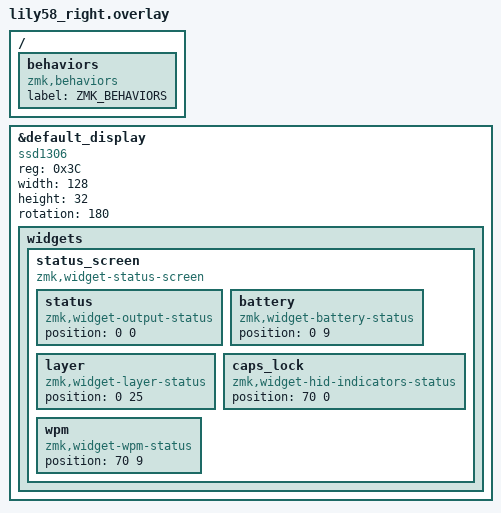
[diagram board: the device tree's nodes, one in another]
#include "../lily58.dtsi"

&default_display {
    compatible = "ssd1306";
    reg = <0x3C>;                    // I2C address
    width = <128>;
    height = <32>;
    rotation = <180>;
    status = "okay";

    widgets {
        status_screen {
            compatible = "zmk,widget-status-screen";
            status {
                compatible = "zmk,widget-output-status";
                position = <0 0>;
            };
            battery {
                compatible = "zmk,widget-battery-status";
                position = <0 9>;
            };
            layer {
                compatible = "zmk,widget-layer-status";
                position = <0 25>;
            };
             caps_lock {
                compatible = "zmk,widget-hid-indicators-status";
                position = <70 0>; // Example position (adjust as needed)
            };
            wpm {
                compatible = "zmk,widget-wpm-status";
                position = <70 9>; // Example position (adjust as needed)
            };

        };
    };
};


/ {
    behaviors {
        compatible = "zmk,behaviors";
        label = "ZMK_BEHAVIORS";
    };
};
